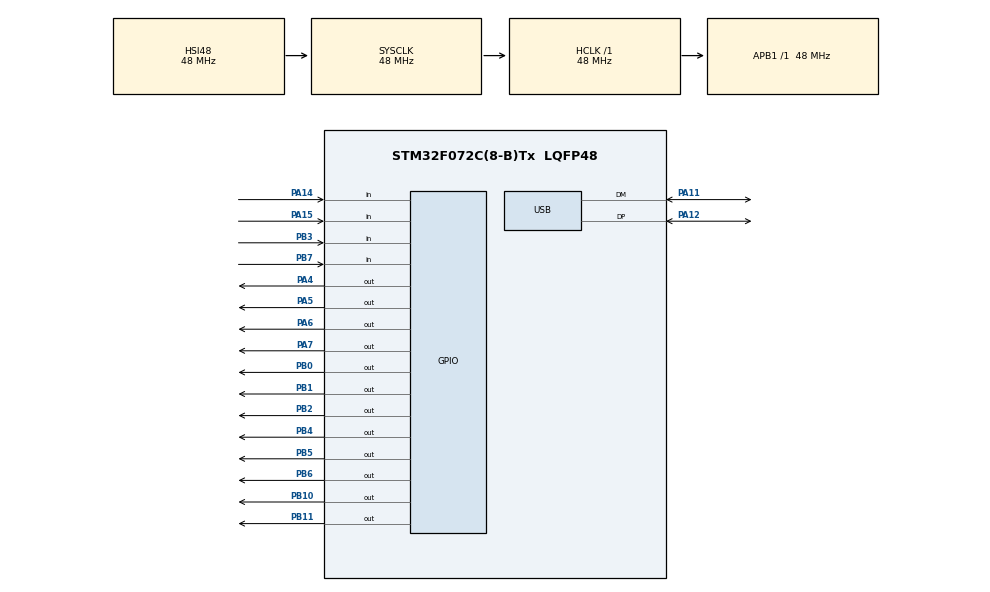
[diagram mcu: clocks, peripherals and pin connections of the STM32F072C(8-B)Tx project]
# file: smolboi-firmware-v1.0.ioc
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Mcu.Family=STM32F0
Mcu.Name=STM32F072C(8-B)Tx
Mcu.Package=LQFP48
NVIC.TIM1_BRK_UP_TRG_COM_IRQn=true\:0\:0\:false\:false\:true\:true\:true\:true
NVIC.TIM1_CC_IRQn=true\:0\:0\:false\:false\:true\:true\:true\:true
NVIC.USB_IRQn=true\:0\:0\:false\:false\:true\:false\:true\:true
PA11.Mode=Device
PA11.Signal=USB_DM
PA12.Mode=Device
PA12.Signal=USB_DP
PA14.GPIO_PuPd=GPIO_PULLDOWN
PA14.Signal=GPIO_Input
PA15.GPIO_PuPd=GPIO_PULLDOWN
PA15.Signal=GPIO_Input
PA4.PinState=GPIO_PIN_RESET
PA4.Signal=GPIO_Output
PA5.PinState=GPIO_PIN_RESET
PA5.Signal=GPIO_Output
PA6.PinState=GPIO_PIN_RESET
PA6.Signal=GPIO_Output
PA7.PinState=GPIO_PIN_RESET
PA7.Signal=GPIO_Output
PB0.PinState=GPIO_PIN_RESET
PB0.Signal=GPIO_Output
PB1.PinState=GPIO_PIN_RESET
PB1.Signal=GPIO_Output
PB10.PinState=GPIO_PIN_RESET
PB10.Signal=GPIO_Output
PB11.PinState=GPIO_PIN_RESET
PB11.Signal=GPIO_Output
PB2.PinState=GPIO_PIN_RESET
PB2.Signal=GPIO_Output
PB3.GPIO_PuPd=GPIO_PULLDOWN
PB3.Signal=GPIO_Input
PB4.PinState=GPIO_PIN_RESET
PB4.Signal=GPIO_Output
PB5.PinState=GPIO_PIN_RESET
PB5.Signal=GPIO_Output
PB6.PinState=GPIO_PIN_RESET
PB6.Signal=GPIO_Output
PB7.GPIO_PuPd=GPIO_PULLDOWN
PB7.Signal=GPIO_Input
ProjectManager.HeapSize=0x200
ProjectManager.StackSize=0x400
ProjectManager.TargetToolchain=STM32CubeIDE
RCC.AHBFreq_Value=48000000
RCC.APB1Freq_Value=48000000
RCC.APB1TimFreq_Value=48000000
RCC.HCLKFreq_Value=48000000
RCC.SYSCLKFreq_VALUE=48000000
RCC.SYSCLKSource=RCC_SYSCLKSOURCE_HSI48
TIM1.Period=1000 - 1
TIM1.Prescaler=4800
USB_DEVICE.CLASS_NAME_FS=HID
USB_DEVICE.PRODUCT_STRING_HID_FS=smolboi
USB_DEVICE.VirtualMode=Hid
USB_DEVICE.VirtualModeFS=Hid_FS
VP_TIM1_VS_ClockSourceINT.Mode=Internal
VP_USB_DEVICE_VS_USB_DEVICE_HID_FS.Mode=HID_FS
board=custom

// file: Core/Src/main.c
/* USER CODE BEGIN Header */
/**
  ******************************************************************************
  * @file           : main.c
  * @brief          : Main program body
  ******************************************************************************
  * @attention
  *
  * Copyright (c) 2025 STMicroelectronics.
  * All rights reserved.
  *
  * This software is licensed under terms that can be found in the LICENSE file
  * in the root directory of this software component.
  * If no LICENSE file comes with this software, it is provided AS-IS.
  *
  ******************************************************************************
  */
/* USER CODE END Header */
#include "main.h"
#include "usb_device.h"

/* USER CODE BEGIN Includes */
//#include "keyboard.c"	// Includes gpio_define.h and usb_keycodes_define.h
/* USER CODE END Includes */

TIM_HandleTypeDef htim1;

/* USER CODE BEGIN PV */
static uint8_t timer1_interrupt = 0;	// Global timer interrupt
uint8_t i;
/* USER CODE END PV */

void SystemClock_Config(void);
static void MX_GPIO_Init(void);
static void MX_TIM1_Init(void);

int main(void)
{

  /* MCU Configuration--------------------------------------------------------*/

  /* Reset of all peripherals, Initializes the Flash interface and the Systick. */
  HAL_Init();

  /* Configure the system clock */
  SystemClock_Config();

  /* Initialize all configured peripherals */
  MX_GPIO_Init();
  MX_TIM1_Init();
  MX_USB_DEVICE_Init();
  /* USER CODE BEGIN 2 */

  // Columns already initiated to high

  // Start timer
  HAL_TIM_Base_Start_IT(&htim1);	// Will throw interrupts automatically to be used in superloop

  /* USER CODE END 2 */

  /* Infinite loop */
  while (1)
  {

    /* USER CODE BEGIN 3 */

	  // Currently 10 Hz
	  if (timer1_interrupt == 1) {
		scanMatrix();
		fillHidInputBuffer();
		fillHidInputReport();
		sendHidReport();
		// Temporary debouncing delay?
		LL_mDelay(20);	// delay 20 ms

		// End of if, reset timer1_interrupt state to 0!
		timer1_interrupt = 0;
	  }
  }
  /* USER CODE END 3 */
}

void SystemClock_Config(void)
{
  RCC_OscInitTypeDef RCC_OscInitStruct = {0};
  RCC_ClkInitTypeDef RCC_ClkInitStruct = {0};
  RCC_PeriphCLKInitTypeDef PeriphClkInit = {0};

  /** Initializes the RCC Oscillators according to the specified parameters
  * in the RCC_OscInitTypeDef structure.
  */
  RCC_OscInitStruct.OscillatorType = RCC_OSCILLATORTYPE_HSI48;
  RCC_OscInitStruct.HSI48State = RCC_HSI48_ON;
  RCC_OscInitStruct.PLL.PLLState = RCC_PLL_NONE;
  if (HAL_RCC_OscConfig(&RCC_OscInitStruct) != HAL_OK)
  {
    Error_Handler();
  }

  /** Initializes the CPU, AHB and APB buses clocks
  */
  RCC_ClkInitStruct.ClockType = RCC_CLOCKTYPE_HCLK|RCC_CLOCKTYPE_SYSCLK
                              |RCC_CLOCKTYPE_PCLK1;
  RCC_ClkInitStruct.SYSCLKSource = RCC_SYSCLKSOURCE_HSI48;
  RCC_ClkInitStruct.AHBCLKDivider = RCC_SYSCLK_DIV1;
  RCC_ClkInitStruct.APB1CLKDivider = RCC_HCLK_DIV1;

  if (HAL_RCC_ClockConfig(&RCC_ClkInitStruct, FLASH_LATENCY_1) != HAL_OK)
  {
    Error_Handler();
  }
  PeriphClkInit.PeriphClockSelection = RCC_PERIPHCLK_USB;
  PeriphClkInit.UsbClockSelection = RCC_USBCLKSOURCE_HSI48;

  if (HAL_RCCEx_PeriphCLKConfig(&PeriphClkInit) != HAL_OK)
  {
    Error_Handler();
  }
}

static void MX_TIM1_Init(void)
{

  TIM_ClockConfigTypeDef sClockSourceConfig = {0};
  TIM_MasterConfigTypeDef sMasterConfig = {0};

  htim1.Instance = TIM1;
  htim1.Init.Prescaler = 4800;
  htim1.Init.CounterMode = TIM_COUNTERMODE_UP;
  htim1.Init.Period = 1000 - 1;
  htim1.Init.ClockDivision = TIM_CLOCKDIVISION_DIV1;
  htim1.Init.RepetitionCounter = 0;
  htim1.Init.AutoReloadPreload = TIM_AUTORELOAD_PRELOAD_DISABLE;
  if (HAL_TIM_Base_Init(&htim1) != HAL_OK)
  {
    Error_Handler();
  }
  sClockSourceConfig.ClockSource = TIM_CLOCKSOURCE_INTERNAL;
  if (HAL_TIM_ConfigClockSource(&htim1, &sClockSourceConfig) != HAL_OK)
  {
    Error_Handler();
  }
  sMasterConfig.MasterOutputTrigger = TIM_TRGO_RESET;
  sMasterConfig.MasterSlaveMode = TIM_MASTERSLAVEMODE_DISABLE;
  if (HAL_TIMEx_MasterConfigSynchronization(&htim1, &sMasterConfig) != HAL_OK)
  {
    Error_Handler();
  }

}

static void MX_GPIO_Init(void)
{
  LL_GPIO_InitTypeDef GPIO_InitStruct = {0};

  /* GPIO Ports Clock Enable */
  LL_AHB1_GRP1_EnableClock(LL_AHB1_GRP1_PERIPH_GPIOA);
  LL_AHB1_GRP1_EnableClock(LL_AHB1_GRP1_PERIPH_GPIOB);

  /**/
  LL_GPIO_ResetOutputPin(GPIOA, LL_GPIO_PIN_4);

  /**/
  LL_GPIO_ResetOutputPin(GPIOA, LL_GPIO_PIN_5);

  /**/
  LL_GPIO_ResetOutputPin(GPIOA, LL_GPIO_PIN_6);

  /**/
  LL_GPIO_ResetOutputPin(GPIOA, LL_GPIO_PIN_7);

  /**/
  LL_GPIO_ResetOutputPin(GPIOB, LL_GPIO_PIN_0);

  /**/
  LL_GPIO_ResetOutputPin(GPIOB, LL_GPIO_PIN_1);

  /**/
  LL_GPIO_ResetOutputPin(GPIOB, LL_GPIO_PIN_2);

  /**/
  LL_GPIO_ResetOutputPin(GPIOB, LL_GPIO_PIN_10);

  /**/
  LL_GPIO_ResetOutputPin(GPIOB, LL_GPIO_PIN_11);

  /**/
  LL_GPIO_ResetOutputPin(GPIOB, LL_GPIO_PIN_4);

  /**/
  LL_GPIO_ResetOutputPin(GPIOB, LL_GPIO_PIN_5);

  /**/
  LL_GPIO_ResetOutputPin(GPIOB, LL_GPIO_PIN_6);

  /**/
  GPIO_InitStruct.Pin = LL_GPIO_PIN_4;
  GPIO_InitStruct.Mode = LL_GPIO_MODE_OUTPUT;
  GPIO_InitStruct.Speed = LL_GPIO_SPEED_FREQ_LOW;
  GPIO_InitStruct.OutputType = LL_GPIO_OUTPUT_PUSHPULL;
  GPIO_InitStruct.Pull = LL_GPIO_PULL_NO;
  LL_GPIO_Init(GPIOA, &GPIO_InitStruct);

  /**/
  GPIO_InitStruct.Pin = LL_GPIO_PIN_5;
  GPIO_InitStruct.Mode = LL_GPIO_MODE_OUTPUT;
  GPIO_InitStruct.Speed = LL_GPIO_SPEED_FREQ_LOW;
  GPIO_InitStruct.OutputType = LL_GPIO_OUTPUT_PUSHPULL;
  GPIO_InitStruct.Pull = LL_GPIO_PULL_NO;
  LL_GPIO_Init(GPIOA, &GPIO_InitStruct);

  /**/
  GPIO_InitStruct.Pin = LL_GPIO_PIN_6;
  GPIO_InitStruct.Mode = LL_GPIO_MODE_OUTPUT;
  GPIO_InitStruct.Speed = LL_GPIO_SPEED_FREQ_LOW;
  GPIO_InitStruct.OutputType = LL_GPIO_OUTPUT_PUSHPULL;
  GPIO_InitStruct.Pull = LL_GPIO_PULL_NO;
  LL_GPIO_Init(GPIOA, &GPIO_InitStruct);

  /**/
  GPIO_InitStruct.Pin = LL_GPIO_PIN_7;
  GPIO_InitStruct.Mode = LL_GPIO_MODE_OUTPUT;
  GPIO_InitStruct.Speed = LL_GPIO_SPEED_FREQ_LOW;
  GPIO_InitStruct.OutputType = LL_GPIO_OUTPUT_PUSHPULL;
  GPIO_InitStruct.Pull = LL_GPIO_PULL_NO;
  LL_GPIO_Init(GPIOA, &GPIO_InitStruct);

  /**/
  GPIO_InitStruct.Pin = LL_GPIO_PIN_0;
  GPIO_InitStruct.Mode = LL_GPIO_MODE_OUTPUT;
  GPIO_InitStruct.Speed = LL_GPIO_SPEED_FREQ_LOW;
  GPIO_InitStruct.OutputType = LL_GPIO_OUTPUT_PUSHPULL;
  GPIO_InitStruct.Pull = LL_GPIO_PULL_NO;
  LL_GPIO_Init(GPIOB, &GPIO_InitStruct);

  /**/
  GPIO_InitStruct.Pin = LL_GPIO_PIN_1;
  GPIO_InitStruct.Mode = LL_GPIO_MODE_OUTPUT;
  GPIO_InitStruct.Speed = LL_GPIO_SPEED_FREQ_LOW;
  GPIO_InitStruct.OutputType = LL_GPIO_OUTPUT_PUSHPULL;
  GPIO_InitStruct.Pull = LL_GPIO_PULL_NO;
  LL_GPIO_Init(GPIOB, &GPIO_InitStruct);

  /**/
  GPIO_InitStruct.Pin = LL_GPIO_PIN_2;
  GPIO_InitStruct.Mode = LL_GPIO_MODE_OUTPUT;
  GPIO_InitStruct.Speed = LL_GPIO_SPEED_FREQ_LOW;
  GPIO_InitStruct.OutputType = LL_GPIO_OUTPUT_PUSHPULL;
  GPIO_InitStruct.Pull = LL_GPIO_PULL_NO;
  LL_GPIO_Init(GPIOB, &GPIO_InitStruct);

  /**/
  GPIO_InitStruct.Pin = LL_GPIO_PIN_10;
  GPIO_InitStruct.Mode = LL_GPIO_MODE_OUTPUT;
  GPIO_InitStruct.Speed = LL_GPIO_SPEED_FREQ_LOW;
  GPIO_InitStruct.OutputType = LL_GPIO_OUTPUT_PUSHPULL;
  GPIO_InitStruct.Pull = LL_GPIO_PULL_NO;
  LL_GPIO_Init(GPIOB, &GPIO_InitStruct);

  /**/
  GPIO_InitStruct.Pin = LL_GPIO_PIN_11;
  GPIO_InitStruct.Mode = LL_GPIO_MODE_OUTPUT;
  GPIO_InitStruct.Speed = LL_GPIO_SPEED_FREQ_LOW;
  GPIO_InitStruct.OutputType = LL_GPIO_OUTPUT_PUSHPULL;
  GPIO_InitStruct.Pull = LL_GPIO_PULL_NO;
  LL_GPIO_Init(GPIOB, &GPIO_InitStruct);

  /**/
  GPIO_InitStruct.Pin = LL_GPIO_PIN_14;
  GPIO_InitStruct.Mode = LL_GPIO_MODE_INPUT;
  GPIO_InitStruct.Pull = LL_GPIO_PULL_DOWN;
  LL_GPIO_Init(GPIOA, &GPIO_InitStruct);

  /**/
  GPIO_InitStruct.Pin = LL_GPIO_PIN_15;
  GPIO_InitStruct.Mode = LL_GPIO_MODE_INPUT;
  GPIO_InitStruct.Pull = LL_GPIO_PULL_DOWN;
  LL_GPIO_Init(GPIOA, &GPIO_InitStruct);

  /**/
  GPIO_InitStruct.Pin = LL_GPIO_PIN_3;
  GPIO_InitStruct.Mode = LL_GPIO_MODE_INPUT;
  GPIO_InitStruct.Pull = LL_GPIO_PULL_DOWN;
  LL_GPIO_Init(GPIOB, &GPIO_InitStruct);

  /**/
  GPIO_InitStruct.Pin = LL_GPIO_PIN_4;
  GPIO_InitStruct.Mode = LL_GPIO_MODE_OUTPUT;
  GPIO_InitStruct.Speed = LL_GPIO_SPEED_FREQ_LOW;
  GPIO_InitStruct.OutputType = LL_GPIO_OUTPUT_PUSHPULL;
  GPIO_InitStruct.Pull = LL_GPIO_PULL_NO;
  LL_GPIO_Init(GPIOB, &GPIO_InitStruct);

  /**/
  GPIO_InitStruct.Pin = LL_GPIO_PIN_5;
  GPIO_InitStruct.Mode = LL_GPIO_MODE_OUTPUT;
  GPIO_InitStruct.Speed = LL_GPIO_SPEED_FREQ_LOW;
  GPIO_InitStruct.OutputType = LL_GPIO_OUTPUT_PUSHPULL;
  GPIO_InitStruct.Pull = LL_GPIO_PULL_NO;
  LL_GPIO_Init(GPIOB, &GPIO_InitStruct);

  /**/
  GPIO_InitStruct.Pin = LL_GPIO_PIN_6;
  GPIO_InitStruct.Mode = LL_GPIO_MODE_OUTPUT;
  GPIO_InitStruct.Speed = LL_GPIO_SPEED_FREQ_LOW;
  GPIO_InitStruct.OutputType = LL_GPIO_OUTPUT_PUSHPULL;
  GPIO_InitStruct.Pull = LL_GPIO_PULL_NO;
  LL_GPIO_Init(GPIOB, &GPIO_InitStruct);

  /**/
  GPIO_InitStruct.Pin = LL_GPIO_PIN_7;
  GPIO_InitStruct.Mode = LL_GPIO_MODE_INPUT;
  GPIO_InitStruct.Pull = LL_GPIO_PULL_DOWN;
  LL_GPIO_Init(GPIOB, &GPIO_InitStruct);

}

/* USER CODE BEGIN 4 */

// Callback: Timer has rolled over
void HAL_TIM_PeriodElapsedCallback(TIM_HandleTypeDef *htim) {
	if (htim == &htim1) {
		timer1_interrupt = 1;
	}
}

/* USER CODE END 4 */

void Error_Handler(void)
{
  __disable_irq();
  while (1)
  {
  }
}
